# G32R502 register map
Vendor: Geehy Semiconductor Co., Ltd.; Series: G32R5; File version: 1.0
CPU: CM52 r0p1, little endian, MPU, FPU, DSP, VTOR, 4 interrupt priority bits
Registers are 32-bit, read-write, reset 0x0 unless marked. A register's access mark holds for its fields unless they carry their own. Offsets are from the block's base; [hi:lo] are bit positions.

## CANFDA
Base 0x40002C00
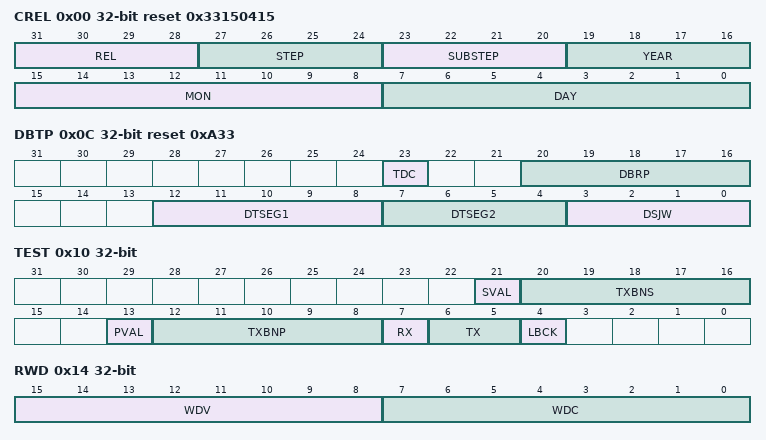
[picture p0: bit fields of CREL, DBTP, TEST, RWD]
0x00 CREL ro reset 0x33150415 — Core Release Register
  [31:28] REL — Core Release
  [27:24] STEP — Step of Core Release
  [23:20] SUBSTEP — Sub-step of Core Release
  [19:16] YEAR
  [15:8] MON — Time Stamp Month
  [7:0] DAY — Time Stamp Day
0x04 ENDN ro reset 0x87654321 — Endian Register
  [31:0] ETV — Endianness Test Value
0x0C DBTP reset 0xA33 — Data Bit Timing & Prescaler Register
  [23] TDC — Transmitter Delay Compensation
  [20:16] DBRP — Data Bit Rate Prescaler
  [12:8] DTSEG1 — Data time segment before sample point
  [7:4] DTSEG2 — Data time segment after sample point
  [3:0] DSJW — Data (Re)Synchronization Jump Width
0x10 TEST
  [21] SVAL — Started Valid
  [20:16] TXBNS — Tx Buffer Number Started
  [13] PVAL — Prepared Valid
  [12:8] TXBNP — Tx Buffer Number Prepared
  [7] RX — Receive Pin
  [6:5] TX — Control of Transmit Pin
  [4] LBCK — Loop Back Mode
0x14 RWD — RAM Watchdog
  [15:8] WDV — Watchdog Value
  [7:0] WDC — Watchdog Configuration
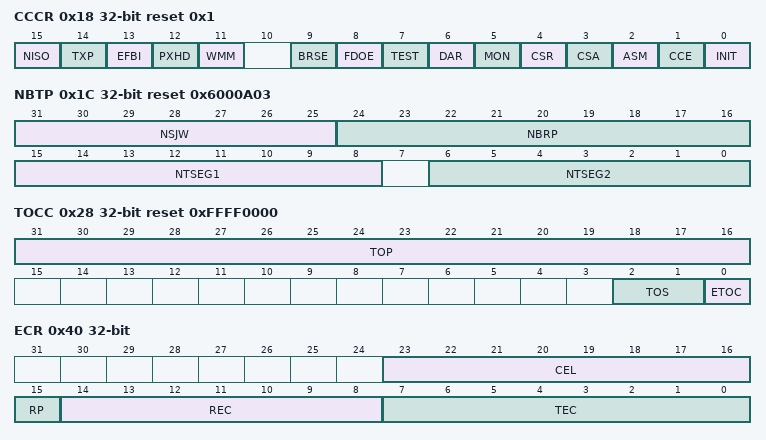
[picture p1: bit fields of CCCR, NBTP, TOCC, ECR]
0x18 CCCR reset 0x1 — CC Control Register
  [15] NISO — Non ISO Operation
  [14] TXP — Transmit Pause
  [13] EFBI — Edge Filtering during Bus Integration
  [12] PXHD — Protocol Exception Handling Disable
  [11] WMM — Wide Message Marker
  [9] BRSE — Bit Rate Switch Enable
  [8] FDOE — FD Operation Enable
  [7] TEST — Test Mode Enable
  [6] DAR — Disable Automatic Retransmission
  [5] MON — Bus Monitoring Mode
  [4] CSR — Clock Stop Request
  [3] CSA — Clock Stop Acknowledge
  [2] ASM — Restricted Operation Mode
  [1] CCE — Configuration Change Enable
  [0] INIT — Initialization
0x1C NBTP reset 0x6000A03 — Nominal Bit Timing & Prescaler Register
  [31:25] NSJW — Nominal (Re)Synchronization Jump Width
  [24:16] NBRP — Nominal Bit Rate Prescaler
  [15:8] NTSEG1 — Nominal Time segment before sample point
  [6:0] NTSEG2 — Nominal Time segment after sample point
0x20 TSCC — Timestamp Counter Configuration
  [19:16] TCP — Timestamp Counter Prescaler
0x24 TSCV — Timestamp Counter Value
  [15:0] TSC — Timestamp Counter
0x28 TOCC reset 0xFFFF0000 — Timeout Counter Configuration
  [31:16] TOP — Timeout Period
  [2:1] TOS — Timeout Select
  [0] ETOC — Enable Timeout Counter
0x2C TOCV ro reset 0xFFFF — Timeout Counter Value
  [15:0] TOC — Timeout Counter
0x40 ECR — Error Counter Register
  [23:16] CEL — CAN Error Logging
  [15] RP — Receive Error Passive
  [14:8] REC — Receive Error Counter
  [7:0] TEC — Transmit Error Counter
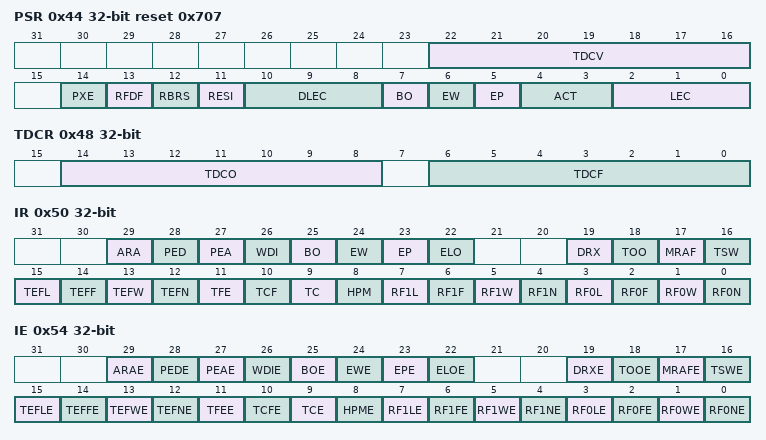
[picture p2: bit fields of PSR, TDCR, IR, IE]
0x44 PSR reset 0x707 — Protocol Status Register
  [22:16] TDCV — Transmitter Delay Compensation Value
  [14] PXE — Protocol Exception Event
  [13] RFDF — Received a CAN FD Message
  [12] RBRS — BRS flag of last received CAN FD Message
  [11] RESI — ESI flag of last received CAN FD Message
  [10:8] DLEC — Data Phase Last Error Code
  [7] BO — Bus_Off Status
  [6] EW — Warning Status
  [5] EP — Error Passive
  [4:3] ACT — Activity
  [2:0] LEC — Last Error Code
0x48 TDCR — Transmitter Delay Compensation Register
  [14:8] TDCO — Transmitter Delay Compensation SSP Offset
  [6:0] TDCF — Transmitter Delay Compensation Filter Window
0x50 IR — Interrupt Register
  [29] ARA — Access to Reserved Address
  [28] PED — Protocol Error in Data Phase
  [27] PEA — Protocol Error in Arbitration Phase
  [26] WDI — Watchdog Interrupt
  [25] BO — Bus_Off Status
  [24] EW — Warning Status
  [23] EP — Error Passive
  [22] ELO — Error Logging Overflow
  [19] DRX — Message stored to Dedicated Rx Buffer
  [18] TOO — Timeout Occurred
  [17] MRAF — Message RAM Access Failure
  [16] TSW — Timestamp Wraparound
  [15] TEFL — Tx Event FIFO Element Lost
  [14] TEFF — Tx Event FIFO Full
  [13] TEFW — Tx Event FIFO Watermark Reached
  [12] TEFN — Tx Event FIFO New Entry
  [11] TFE — Tx FIFO Empty
  [10] TCF — Transmission Cancellation Finished
  [9] TC — Transmission Completed
  [8] HPM — High Priority Message
  [7] RF1L — Rx FIFO 1 Message Lost
  [6] RF1F — Rx FIFO 1 Full
  [5] RF1W — Rx FIFO 1 Watermark Reached
  [4] RF1N — Rx FIFO 1 New Message
  [3] RF0L — Rx FIFO 0 Message Lost
  [2] RF0F — Rx FIFO 0 Full
  [1] RF0W — Rx FIFO 0 Watermark Reached
  [0] RF0N — Rx FIFO 0 New Message
0x54 IE — Interrupt Enable
  [29] ARAE — Access to Reserved Address Enable
  [28] PEDE — Protocol Error in Data Phase Enable
  [27] PEAE — Protocol Error in Arbitration Phase Enable
  [26] WDIE — Watchdog Interrupt Enable
  [25] BOE — Bus_Off Status Interrupt Enable
  [24] EWE — Warning Status Interrupt Enable
  [23] EPE — Error Passive Interrupt Enable
  [22] ELOE — Error Logging Overflow Interrupt Enable
  [19] DRXE — Message stored to Dedicated Rx Buffer IE
  [18] TOOE — Timeout Occurred Interrupt Enable
  [17] MRAFE — Message RAM Access Failure Interrupt Enable
  [16] TSWE — Timestamp Wraparound Interrupt Enable
  [15] TEFLE — Tx Event FIFO Event Lost Interrupt Enable
  [14] TEFFE — Tx Event FIFO Full Interrupt Enable
  [13] TEFWE — Tx Event FIFO Watermark Interrupt Enable
  [12] TEFNE — Tx Event FIFO New Entry Interrupt Enable
  [11] TFEE — Tx FIFO Empty Interrupt Enable
  [10] TCFE — Transmission Cancellation Finished IE
  [9] TCE — Transmission Completed Interrupt Enable
  [8] HPME — High Priority Message Interrupt Enable
  [7] RF1LE — Rx FIFO 1 Message Lost Interrupt Enable
  [6] RF1FE — Rx FIFO 1 Full Interrupt Enable
  [5] RF1WE — Rx FIFO 1 Watermark Interrupt Enable
  [4] RF1NE — Rx FIFO 1 New Message Interrupt Enable
  [3] RF0LE — Rx FIFO 0 Message Lost Interrupt Enable
  [2] RF0FE — Rx FIFO 0 Full Interrupt Enable
  [1] RF0WE — Rx FIFO 0 Watermark Interrupt Enable
  [0] RF0NE — Rx FIFO 0 New Message Interrupt Enable
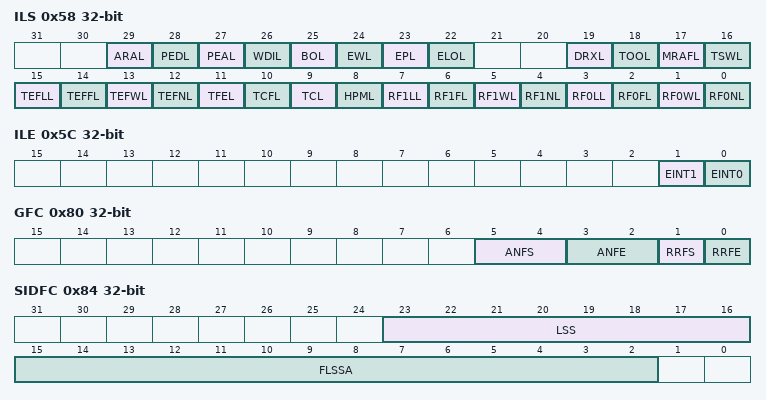
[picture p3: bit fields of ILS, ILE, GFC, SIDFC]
0x58 ILS — Interrupt Line Select
  [29] ARAL — Access to Reserved Address Line
  [28] PEDL — Protocol Error in Data Phase Line
  [27] PEAL — Protocol Error in Arbitration Phase Line
  [26] WDIL — Watchdog Interrupt Line
  [25] BOL — Bus_Off Status Interrupt Line
  [24] EWL — Warning Status Interrupt Line
  [23] EPL — Error Passive Interrupt Line
  [22] ELOL — Error Logging Overflow Interrupt Line
  [19] DRXL — Message stored to Dedicated Rx Buffer Line
  [18] TOOL — Timeout Occurred Interrupt Line
  [17] MRAFL — Message RAM Access Failure Interrupt Line
  [16] TSWL — Timestamp Wraparound Interrupt Line
  [15] TEFLL — Tx Event FIFO Event Lost Interrupt Line
  [14] TEFFL — Tx Event FIFO Full Interrupt Line
  [13] TEFWL — Tx Event FIFO Watermark Reached Interrupt Line
  [12] TEFNL — Tx Event FIFO New Entry Interrupt Line
  [11] TFEL — Tx FIFO Empty Interrupt Line
  [10] TCFL — Transmission Cancellation Finished Interrupt Line
  [9] TCL — Transmission Completed Interrupt Line
  [8] HPML — High Priority Message Interrupt Line
  [7] RF1LL — Rx FIFO 1 Message Lost Interrupt Line
  [6] RF1FL — Rx FIFO 1 Full Interrupt Line
  [5] RF1WL — Rx FIFO 1 Watermark Reached Interrupt Line
  [4] RF1NL — Rx FIFO 1 New Message Interrupt Line
  [3] RF0LL — Rx FIFO 0 Message Lost Interrupt Line
  [2] RF0FL — Rx FIFO 0 Full Interrupt Line
  [1] RF0WL — Rx FIFO 0 Watermark Reached Interrupt Line
  [0] RF0NL — Rx FIFO 0 New Message Interrupt Line
0x5C ILE — Interrupt Line Enable
  [1] EINT1 — Enable Interrupt Line 1
  [0] EINT0 — Enable Interrupt Line 0
0x80 GFC — Global Filter Configuration
  [5:4] ANFS — Accept Non-matching Frames Standard
  [3:2] ANFE — Accept Non-matching Frames Extended
  [1] RRFS — Reject Remote Frames Standard
  [0] RRFE — Reject Remote Frames Extended
0x84 SIDFC — Standard ID Filter Configuration
  [23:16] LSS — List Size Standard
  [15:2] FLSSA — Filter List Standard Start Address
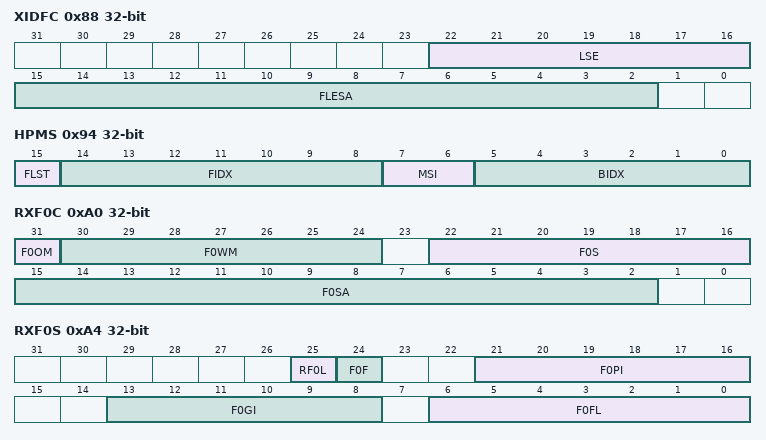
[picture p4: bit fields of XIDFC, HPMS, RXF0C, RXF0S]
0x88 XIDFC — Extended ID Filter Configuration
  [22:16] LSE — List Size Extended
  [15:2] FLESA — Filter List Extended Start Address
0x90 XIDAM reset 0x1FFFFFFF — Extended ID AND Mask
  [28:0] EIDM — Extended ID Mask
0x94 HPMS ro — High Priority Message Status
  [15] FLST — Filter List
  [14:8] FIDX — Filter Index
  [7:6] MSI — Message Storage Indicator
  [5:0] BIDX — Buffer Index
0x98 NDAT1 — New Data 1
  [31:0] ND — New Data Buffers 0..31
0x9C NDAT2 — New Data 2
  [31:0] ND — New Data Buffers 32..63
0xA0 RXF0C — Rx FIFO 0 Configuration
  [31] F0OM — FIFO 0 Operation Mode
  [30:24] F0WM — Rx FIFO 0 Watermark
  [22:16] F0S — Rx FIFO 0 Size
  [15:2] F0SA — Rx FIFO 0 Start Address
0xA4 RXF0S ro — Rx FIFO 0 Status
  [25] RF0L — Rx FIFO 0 Message Lost
  [24] F0F — Rx FIFO 0 Full
  [21:16] F0PI — Rx FIFO 0 Put Index
  [13:8] F0GI — Rx FIFO 0 Get Index
  [6:0] F0FL — Rx FIFO 0 Fill Level
0xA8 RXF0A — Rx FIFO 0 Acknowledge
  [5:0] F0AI — Rx FIFO 0 Acknowledge Index
0xAC RXBC — Rx Buffer Configuration
  [15:2] RBSA — Rx Buffer Start Address
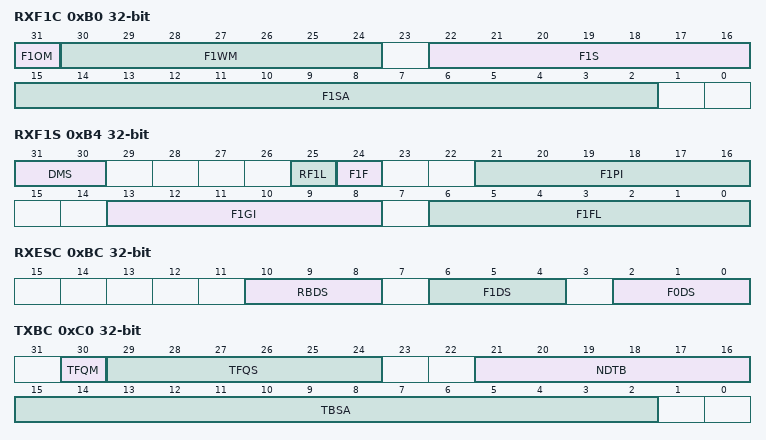
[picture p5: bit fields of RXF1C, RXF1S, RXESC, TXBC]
0xB0 RXF1C — Rx FIFO 1 Configuration
  [31] F1OM — FIFO 1 Operation Mode
  [30:24] F1WM — Rx FIFO 1 Watermark
  [22:16] F1S — Rx FIFO 1 Size
  [15:2] F1SA — Rx FIFO 1 Start Address
0xB4 RXF1S ro — Rx FIFO 1 Status
  [31:30] DMS — Debug Message Status
  [25] RF1L — Rx FIFO 1 Message Lost
  [24] F1F — Rx FIFO 1 Full
  [21:16] F1PI — Rx FIFO 1 Put Index
  [13:8] F1GI — Rx FIFO 1 Get Index
  [6:0] F1FL — Rx FIFO 1 Fill Level
0xB8 RXF1A — Rx FIFO 1 Acknowledge
  [5:0] F1AI — Rx FIFO 1 Acknowledge Index
0xBC RXESC — Rx Buffer / FIFO Element Size Configuration
  [10:8] RBDS — Rx Buffer Data Field Size
  [6:4] F1DS — Rx FIFO 1 Data Field Size
  [2:0] F0DS — Rx FIFO 0 Data Field Size
0xC0 TXBC — Tx Buffer Configuration
  [30] TFQM — Tx FIFO/Queue Mode
  [29:24] TFQS — Transmit FIFO/Queue Size
  [21:16] NDTB — Number of Dedicated Transmit Buffers
  [15:2] TBSA — Tx Buffers Start Address
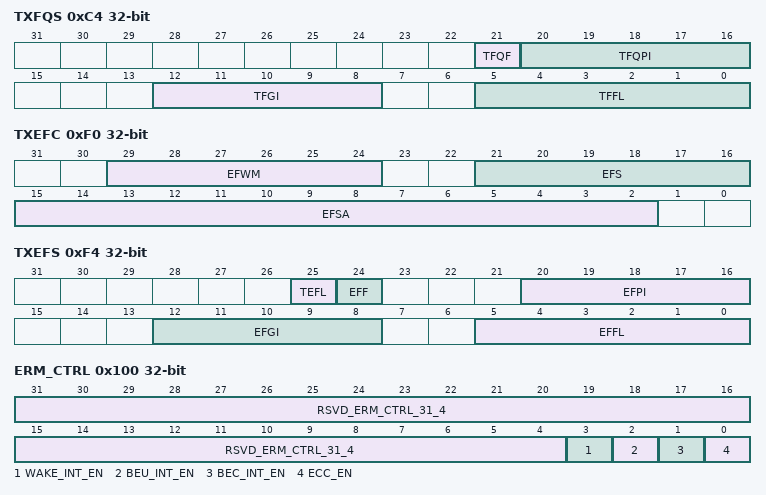
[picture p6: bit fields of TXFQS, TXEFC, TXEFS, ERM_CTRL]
0xC4 TXFQS ro — Tx FIFO/Queue Status
  [21] TFQF — Tx FIFO/Queue Full
  [20:16] TFQPI — Tx FIFO/Queue Put Index
  [12:8] TFGI — Tx FIFO Get Index
  [5:0] TFFL — Tx FIFO Free Level
0xC8 TXESC — Tx Buffer Element Size Configuration
  [2:0] TBDS — Tx Buffer Data Field Size
0xCC TXBRP ro — Tx Buffer Request Pending
  [31:0] TRP — Transmission Request Pending
0xD0 TXBAR — Tx Buffer Add Request
  [31:0] AR — Add Request
0xD4 TXBCR — Tx Buffer Cancellation Request
  [31:0] CR — Cancellation Request
0xD8 TXBTO ro — Tx Buffer Transmission Occurred
  [31:0] TO — Transmission Occurred
0xDC TXBCF ro — Tx Buffer Cancellation Finished
  [31:0] CF — Cancellation Finished
0xE0 TXBTIE — Tx Buffer Transmission Interrupt Enable
  [31:0] TIE — Transmission Interrupt Enable
0xE4 TXBCIE — Tx Buffer Cancellation Finished Interrupt Enable
  [31:0] CFIE — Cancellation Finished Interrupt Enable
0xF0 TXEFC — Tx Event FIFO Configuration
  [29:24] EFWM — Event FIFO Watermark
  [21:16] EFS — Event FIFO Size
  [15:2] EFSA — Event FIFO Start Address
0xF4 TXEFS ro — Tx Event FIFO Status
  [25] TEFL — Tx Event FIFO Element Lost
  [24] EFF — Event FIFO Full
  [20:16] EFPI — Event FIFO Put Index
  [12:8] EFGI — Event FIFO Get Index
  [5:0] EFFL — Event FIFO Fill Level
0xF8 TXEFA — Tx Event FIFO Acknowledge
  [4:0] EFAI — Event FIFO Acknowledge Index
0x100 ERM_CTRL — ERM Control Register
  [31:4] RSVD_ERM_CTRL_31_4 ro — Reserved
  [3] WAKE_INT_EN — CANFD wakeup interrupt enable
  [2] BEU_INT_EN — Bit error uncorrected interrupt enable
  [1] BEC_INT_EN — Bit error corrected interrupt enable
  [0] ECC_EN — Enable SRAM ECC check and global interrupt for SRAM ECC check
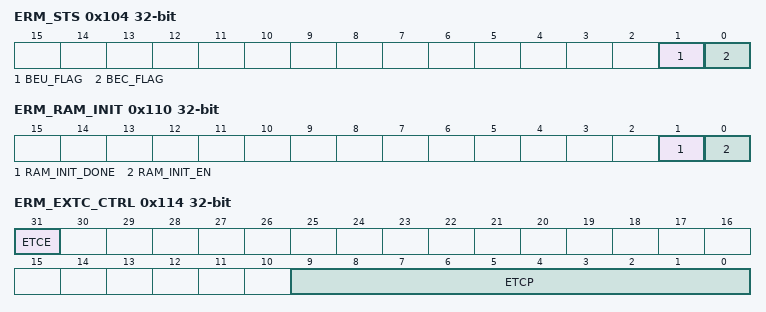
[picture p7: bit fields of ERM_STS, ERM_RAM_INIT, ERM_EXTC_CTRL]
0x104 ERM_STS — ERM Status Register
  [1] BEU_FLAG — Detect multiple bit errors and cannot be corrected
  [0] BEC_FLAG — Detect single bit error and can be corrected
0x108 ERM_ECC_ADDR_LOG — ERM ECC Address Log
  [9:0] ERR_ADDR — The address of the error found
0x10C ERM_ECC_DATA_LOG
  [31:0] ERR_DATA — The data of the error found
0x110 ERM_RAM_INIT — ERM RAM Initialization Control
  [1] RAM_INIT_DONE ro — The flag of RAM initialization
  [0] RAM_INIT_EN — RAM initialization request
0x114 ERM_EXTC_CTRL — ERM External Timestamp Counter Control
  [31] ETCE — External Timestamp Counter Enable
  [9:0] ETCP — External Timestamp Prescaler Value
0x118 ERM_EXTC_VAL ro — ERM External Timestamp Counter Value
  [15:0] ETSC — External Timestamp Counter
